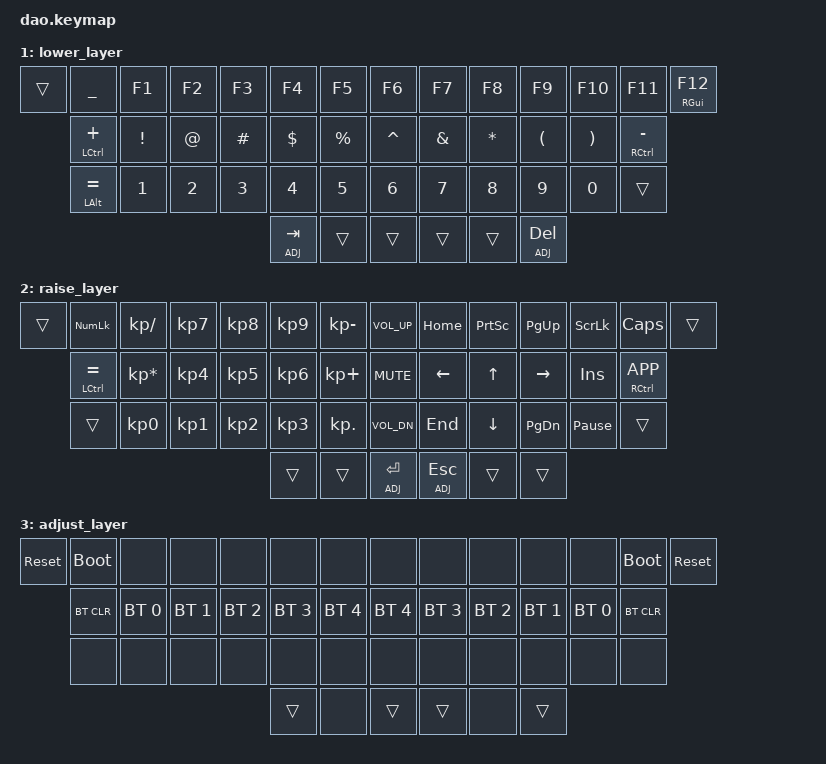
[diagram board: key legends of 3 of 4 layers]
/*
 * Copyright (c) 2021 Rafael Yumagulov
 *
 * SPDX-License-Identifier: MIT
 */

#include <behaviors.dtsi>
#include <dt-bindings/zmk/keys.h>
#include <dt-bindings/zmk/bt.h>

#define DEF 0
#define LWR 1
#define RSE 2
#define ADJ 3

&sl { release-after-ms = <200>; };  // Sticky Layer
&mt { quick_tap_ms = <200>; };      // Momentary Tap


/ {
        keymap {
                compatible = "zmk,keymap";

                default_layer {
                        bindings = <
  &trans &kp TAB    &kp Q &kp W &kp E &kp R &kp T              &kp Y  &kp U  &kp I     &kp O   &kp P    &kp DEL
  &trans &kp LALT &kp A &kp S &kp D &kp F &kp G &kp H          &kp J  &kp K     &kp L   &kp QUOT &mt RALT SQT
         &kp LSFT  &kp Z &kp X &kp C &kp V &kp B &kp N         &kp M  &kp COMMA &kp DOT &kp FSLH &sl ADJ
                   &kp LCTRL &mt RET LGUI &mt LWR TAB          &kp SPACE &mt RSE BSPC &kp RGUI &kp RCTRL
                        >;
                };
                lower_layer {
                        bindings = <
   &trans &kp UNDER      &kp F1   &kp F2 &kp F3   &kp F4   &kp F5           &kp F6    &kp F7   &kp F8   &kp F9   &kp F10  &kp F11 &mt RGUI F12
          &mt LCTRL PLUS &kp EXCL &kp AT &kp HASH &kp DLLR &kp PRCNT        &kp CARET &kp AMPS &kp STAR &kp LPAR &kp RPAR &mt RCTRL MINUS
          &mt LALT EQUAL &kp N1   &kp N2 &kp N3   &kp N4   &kp N5           &kp N6    &kp N7   &kp N8   &kp N9   &kp N0   &trans
                                              &mt ADJ TAB &trans &trans   &trans &trans &mt ADJ DEL
                        >;
                };

                raise_layer {
                        bindings = <
   &trans &kp KP_NUM      &kp KP_SLASH    &kp KP_N7 &kp KP_N8 &kp KP_N9 &kp KP_MINUS        &kp C_VOL_UP &kp HOME &kp PSCRN &kp PG_UP &kp SLCK &kp CAPS &trans
          &mt LCTRL EQUAL &kp KP_MULTIPLY &kp KP_N4 &kp KP_N5 &kp KP_N6 &kp KP_PLUS         &kp C_MUTE   &kp LEFT &kp UP    &kp RIGHT &kp INS  &mt RCTRL K_APP
          &trans          &kp KP_N0       &kp KP_N1 &kp KP_N2 &kp KP_N3 &kp KP_DOT          &kp C_VOL_DN &kp END  &kp DOWN  &kp PG_DN &kp PAUSE_BREAK &trans
                                                           &trans &trans &mt ADJ RET   &mt ADJ ESC &trans &trans
                        >;
                };
                adjust_layer {
                        bindings = <
   &sys_reset &bootloader  &none        &none        &none        &none        &none              &none        &none        &none        &none        &none         &bootloader &sys_reset
          &bt BT_CLR   &bt BT_SEL 0 &bt BT_SEL 1 &bt BT_SEL 2 &bt BT_SEL 3 &bt BT_SEL 4       &bt BT_SEL 4 &bt BT_SEL 3 &bt BT_SEL 2 &bt BT_SEL 1 &bt BT_SEL 0  &bt BT_CLR
          &none        &none        &none        &none        &none        &none              &none        &none        &none        &none        &none         &none
                                                                    &trans &none &trans   &trans &none &trans
                        >;
                };
        };
};
